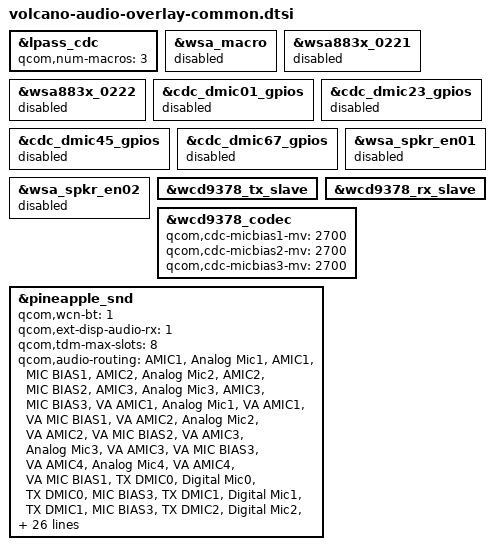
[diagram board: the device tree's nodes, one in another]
&lpass_cdc {
    qcom,num-macros = <3>;
};

&wsa_macro{
    status = "disabled";
};

&wsa883x_0221{
    status = "disabled";
};

&wsa883x_0222{
    status = "disabled";
};

&cdc_dmic01_gpios{
    status = "disabled";
};

&cdc_dmic23_gpios{
    status = "disabled";
};

&cdc_dmic45_gpios{
    status = "disabled";
};

&cdc_dmic67_gpios{
    status = "disabled";
};

&wsa_spkr_en01{
    status = "disabled";
};

&wsa_spkr_en02{
    status = "disabled";
};

&wcd9378_tx_slave{
    status = "okay";
};

&wcd9378_rx_slave{
    status = "okay";
};

&wcd9378_codec{
    status = "okay";
    qcom,cdc-micbias1-mv = <2700>;
    qcom,cdc-micbias2-mv = <2700>;
    qcom,cdc-micbias3-mv = <2700>;
};

&pineapple_snd{
    qcom,wcn-bt = <1>;
    qcom,ext-disp-audio-rx = <1>;
    qcom,tdm-max-slots = <8>;
    qcom,audio-routing =
        "AMIC1", "Analog Mic1",
        "AMIC1", "MIC BIAS1",
        "AMIC2", "Analog Mic2",
        "AMIC2", "MIC BIAS2",
        "AMIC3", "Analog Mic3",
        "AMIC3", "MIC BIAS3",
        "VA AMIC1", "Analog Mic1",
        "VA AMIC1", "VA MIC BIAS1",
        "VA AMIC2", "Analog Mic2",
        "VA AMIC2", "VA MIC BIAS2",
        "VA AMIC3", "Analog Mic3",
        "VA AMIC3", "VA MIC BIAS3",
        "VA AMIC4", "Analog Mic4",
        "VA AMIC4", "VA MIC BIAS1",
        "TX DMIC0", "Digital Mic0",
        "TX DMIC0", "MIC BIAS3",
        "TX DMIC1", "Digital Mic1",
        "TX DMIC1", "MIC BIAS3",
        "TX DMIC2", "Digital Mic2",
        "TX DMIC2", "MIC BIAS1",
        "TX DMIC3", "Digital Mic3",
        "TX DMIC3", "MIC BIAS1",
        "IN1_HPHL", "HPHL_OUT",
        "IN2_HPHR", "HPHR_OUT",
        "IN3_AUX", "AUX_OUT",
        "RX_TX DEC0_INP", "TX DEC0 MUX",
        "RX_TX DEC1_INP", "TX DEC1 MUX",
        "RX_TX DEC2_INP", "TX DEC2 MUX",
        "RX_TX DEC3_INP", "TX DEC3 MUX",
        "VA SWR_INPUT", "VA_SWR_CLK",
        "VA_AIF1 CAP", "VA_SWR_CLK",
        "VA_AIF2 CAP", "VA_SWR_CLK",
        "VA_AIF3 CAP", "VA_SWR_CLK";
    qcom,msm-mbhc-hs-mic-max-threshold-mv = <2600>;
    qcom,msm-mbhc-hs-mic-min-threshold-mv = <112>;/* 75*2700/1800 */
    qcom,msm-mbhc-usbc-audio-supported = <1>;
    qcom,msm-mbhc-hphl-swh = <0>;
    qcom,msm-mbhc-gnd-swh = <0>; /* follow bale*/
    oplus,mbhc-headset-micbias-alwayon = <1>;

    qcom,cdc-dmic01-gpios = <&cdc_dmic01_gpios>;
    qcom,cdc-dmic23-gpios = <&cdc_dmic23_gpios>;
    qcom,cdc-dmic45-gpios = <&cdc_dmic45_gpios>;
    asoc-codec  = <&stub_codec>, <&lpass_cdc>,
               <&wcd9378_codec>;
    asoc-codec-names = "msm-stub-codec.1", "lpass-cdc",
               "wcd9378_codec";
    qcom,wsa-max-devs = <0>;
    qcom,msm_audio_ssr_devs = <&audio_gpr>, <&lpi_tlmm>,
               <&lpass_cdc>;
    oplus,pa_manager = <1>;
};
